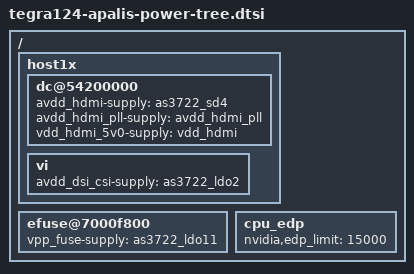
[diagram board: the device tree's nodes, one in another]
/*
 * arch/arm/boot/dts/tegra124-platforms/tegra124-jetson-power-tree-pm375-0000-c00.dtsi
 *
 * Copyright (c) 2014, NVIDIA CORPORATION.  All rights reserved.
 *
 * This program is free software; you can redistribute it and/or modify
 * it under the terms of the GNU General Public License as published by
 * the Free Software Foundation; either version 2 of the License, or
 * (at your option) any later version.
 *
 * This program is distributed in the hope that it will be useful, but WITHOUT
 * ANY WARRANTY; without even the implied warranty of MERCHANTABILITY or
 * FITNESS FOR A PARTICULAR PURPOSE.  See the GNU General Public License for
 * more details.
 *
 * You should have received a copy of the GNU General Public License along
 * with this program; if not, write to the Free Software Foundation, Inc.,
 * 51 Franklin Street, Fifth Floor, Boston, MA  02110-1301, USA.
 */

#include "tegra124-platforms/tegra124-apalis-pmic.dtsi"
#include "tegra124-platforms/tegra124-apalis-fixed.dtsi"

/ {
	host1x {
		/* tegradc.0 */
		dc@54200000 {
			avdd_hdmi-supply = <&as3722_sd4>;
			avdd_hdmi_pll-supply = <&avdd_hdmi_pll>;
			vdd_hdmi_5v0-supply = <&vdd_hdmi>;
		};

		vi {
			avdd_dsi_csi-supply = <&as3722_ldo2>;
		};
	};


	efuse@7000f800 {
		vpp_fuse-supply = <&as3722_ldo11>;
	};

	cpu_edp {
		nvidia,edp_limit = <15000>;
	};
};
